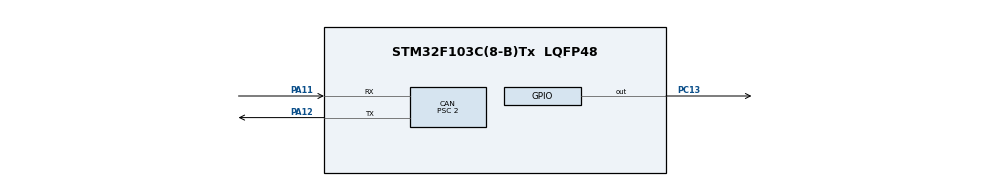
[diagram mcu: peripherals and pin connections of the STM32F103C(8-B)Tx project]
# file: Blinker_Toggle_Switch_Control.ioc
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CAN.BS1=CAN_BS1_13TQ
CAN.BS2=CAN_BS2_2TQ
CAN.CalculateBaudRate=250000
CAN.CalculateTimeBit=4000
CAN.CalculateTimeQuantum=250.0
CAN.Prescaler=2
Mcu.Family=STM32F1
Mcu.Name=STM32F103C(8-B)Tx
Mcu.Package=LQFP48
NVIC.PriorityGroup=NVIC_PRIORITYGROUP_4
NVIC.TIM1_UP_IRQn=true\:15\:0\:false\:false\:true\:false\:true\:true
NVIC.TimeBase=TIM1_UP_IRQn
NVIC.TimeBaseIP=TIM1
PA11.Mode=CAN_Activate
PA11.Signal=CAN_RX
PA12.Mode=CAN_Activate
PA12.Signal=CAN_TX
PA13.Mode=Serial_Wire
PA13.Signal=SYS_JTMS-SWDIO
PA14.Mode=Serial_Wire
PA14.Signal=SYS_JTCK-SWCLK
PC13-TAMPER-RTC.Signal=GPIO_Output
ProjectManager.HeapSize=0x200
ProjectManager.StackSize=0x400
ProjectManager.TargetToolchain=CMake
RCC.APB1Freq_Value=8000000
RCC.APB2Freq_Value=8000000
VP_SYS_VS_tim1.Mode=TIM1
board=custom

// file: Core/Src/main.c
/* USER CODE BEGIN Header */
/**
  ******************************************************************************
  * @file           : main.c
  * @brief          : Main program body
  ******************************************************************************
  * @attention
  *
  * Copyright (c) 2025 STMicroelectronics.
  * All rights reserved.
  *
  * This software is licensed under terms that can be found in the LICENSE file
  * in the root directory of this software component.
  * If no LICENSE file comes with this software, it is provided AS-IS.
  *
  ******************************************************************************
  */
/* USER CODE END Header */
#include "main.h"

/* USER CODE BEGIN PD */

//#define TOGGLE_INTERVAL_MS 500
#define POLLING_INTERVAL_MS 5 // Poll every 5ms to allow debouncing

/* USER CODE END PD */

CAN_HandleTypeDef hcan;

/* USER CODE BEGIN PV */

uint8_t blinker_state = HBLINKER_enuBlinker_OFF;
uint32_t last_toggle_time = 0;
uint8_t led_state = 0;
uint32_t last_poll_time = 0;

static TaskHandle_t Main_xBlinkerSwitchCANTaskHandle = NULL;

/* USER CODE END PV */

void SystemClock_Config(void);
static void MX_GPIO_Init(void);
static void MX_CAN_Init(void);
/* USER CODE BEGIN PFP */

void Main_vBlinkerSwitchCANTask(void *Copy_pvParams);

void CAN_Tx(HBLINKER_enuBlinkerState_t Copy_pvU8SwitchState);

/* USER CODE END PFP */

int main(void)
{

  /* USER CODE BEGIN 1 */

  BaseType_t Loc_xTaskStatus = pdFAIL;

  /* USER CODE END 1 */

  /* MCU Configuration--------------------------------------------------------*/

  /* Reset of all peripherals, Initializes the Flash interface and the Systick. */
  HAL_Init();

  /* Configure the system clock */
  SystemClock_Config();

  /* Initialize all configured peripherals */
  MX_GPIO_Init();
  MX_CAN_Init();
  /* USER CODE BEGIN 2 */

  HBLINKER_vInit(); // Initialize the blinker driver (configures PA1, PA2)
  //HAL_GPIO_WritePin(GPIOC, GPIO_PIN_13, GPIO_PIN_SET); // LED off (active low)

  Loc_xTaskStatus = xTaskCreate(&Main_vBlinkerSwitchCANTask, "BlinkerSwitchCANTask", 200UL, NULL, 0UL, &Main_xBlinkerSwitchCANTaskHandle);
  configASSERT(Loc_xTaskStatus == pdPASS);

  // CAN go to normal mode
  CAN_FilterTypeDef sFilterConfig;

  sFilterConfig.FilterBank = 0;
  sFilterConfig.FilterMode = CAN_FILTERMODE_IDMASK;
  sFilterConfig.FilterScale = CAN_FILTERSCALE_32BIT;
  sFilterConfig.FilterIdHigh = 0x0000;
  sFilterConfig.FilterIdLow = 0x0000;
  sFilterConfig.FilterMaskIdHigh = 0x0000;
  sFilterConfig.FilterMaskIdLow = 0x0000;
  sFilterConfig.FilterFIFOAssignment = CAN_FILTER_FIFO0;
  sFilterConfig.FilterActivation = ENABLE;
  sFilterConfig.SlaveStartFilterBank = 14;

  HAL_CAN_ConfigFilter(&hcan, &sFilterConfig);

  HAL_CAN_Start(&hcan);

  vTaskStartScheduler();

  /* USER CODE END 2 */

  /* Infinite loop */
  while (1)
  {

  }
}

void SystemClock_Config(void)
{
  RCC_OscInitTypeDef RCC_OscInitStruct = {0};
  RCC_ClkInitTypeDef RCC_ClkInitStruct = {0};

  /** Initializes the RCC Oscillators according to the specified parameters
  * in the RCC_OscInitTypeDef structure.
  */
  RCC_OscInitStruct.OscillatorType = RCC_OSCILLATORTYPE_HSI;
  RCC_OscInitStruct.HSIState = RCC_HSI_ON;
  RCC_OscInitStruct.HSICalibrationValue = RCC_HSICALIBRATION_DEFAULT;
  RCC_OscInitStruct.PLL.PLLState = RCC_PLL_NONE;
  if (HAL_RCC_OscConfig(&RCC_OscInitStruct) != HAL_OK)
  {
    Error_Handler();
  }

  /** Initializes the CPU, AHB and APB buses clocks
  */
  RCC_ClkInitStruct.ClockType = RCC_CLOCKTYPE_HCLK|RCC_CLOCKTYPE_SYSCLK
                              |RCC_CLOCKTYPE_PCLK1|RCC_CLOCKTYPE_PCLK2;
  RCC_ClkInitStruct.SYSCLKSource = RCC_SYSCLKSOURCE_HSI;
  RCC_ClkInitStruct.AHBCLKDivider = RCC_SYSCLK_DIV1;
  RCC_ClkInitStruct.APB1CLKDivider = RCC_HCLK_DIV1;
  RCC_ClkInitStruct.APB2CLKDivider = RCC_HCLK_DIV1;

  if (HAL_RCC_ClockConfig(&RCC_ClkInitStruct, FLASH_LATENCY_0) != HAL_OK)
  {
    Error_Handler();
  }
}

static void MX_CAN_Init(void)
{

  hcan.Instance = CAN1;
  hcan.Init.Prescaler = 2;
  hcan.Init.Mode = CAN_MODE_NORMAL;
  hcan.Init.SyncJumpWidth = CAN_SJW_1TQ;
  hcan.Init.TimeSeg1 = CAN_BS1_13TQ;
  hcan.Init.TimeSeg2 = CAN_BS2_2TQ;
  hcan.Init.TimeTriggeredMode = DISABLE;
  hcan.Init.AutoBusOff = DISABLE;
  hcan.Init.AutoWakeUp = DISABLE;
  hcan.Init.AutoRetransmission = DISABLE;
  hcan.Init.ReceiveFifoLocked = DISABLE;
  hcan.Init.TransmitFifoPriority = DISABLE;
  if (HAL_CAN_Init(&hcan) != HAL_OK)
  {
    Error_Handler();
  }

}

static void MX_GPIO_Init(void)
{
  //GPIO_InitTypeDef GPIO_InitStruct = {0};

  /* GPIO Ports Clock Enable */

  //__HAL_RCC_GPIOC_CLK_ENABLE();

  __HAL_RCC_GPIOA_CLK_ENABLE();

  /*Configure GPIO pin Output Level */

  //HAL_GPIO_WritePin(GPIOC, GPIO_PIN_13, GPIO_PIN_RESET);

  /*Configure GPIO pin : PC13 */

  /*GPIO_InitStruct.Pin = GPIO_PIN_13;
  GPIO_InitStruct.Mode = GPIO_MODE_OUTPUT_PP;
  GPIO_InitStruct.Pull = GPIO_NOPULL;
  GPIO_InitStruct.Speed = GPIO_SPEED_FREQ_LOW;
  HAL_GPIO_Init(GPIOC, &GPIO_InitStruct);*/

}

/* USER CODE BEGIN 4 */

void Main_vBlinkerSwitchCANTask(void *Copy_pvParams){

  TickType_t Loc_xLastWakeTime;
  const TickType_t Loc_xPeriodicity = pdMS_TO_TICKS(50);

  Loc_xLastWakeTime = xTaskGetTickCount();

  for ( ; ; )
  {
    uint32_t current_time = HAL_GetTick();
    if (current_time - last_poll_time >= POLLING_INTERVAL_MS)
    {
        if (HBLINKER_enuGetBLINKERState(HBLINKER_BLINKER_TOGGLE, &blinker_state) == HBLINKER_enuError_OK)
        {
            if (blinker_state == HBLINKER_enuBlinker_RIGHT) // RIGHT
            {
                CAN_Tx(HBLINKER_enuBlinker_RIGHT);

                /*if (current_time - last_toggle_time >= TOGGLE_INTERVAL_MS)
                {
                    led_state = !led_state;
                    HAL_GPIO_WritePin(GPIOC, GPIO_PIN_13, led_state ? GPIO_PIN_RESET : GPIO_PIN_SET);
                    last_toggle_time = current_time;
                }*/
            }
            else if (blinker_state == HBLINKER_enuBlinker_LEFT) // LEFT
            {
                CAN_Tx(HBLINKER_enuBlinker_LEFT);

                //HAL_GPIO_WritePin(GPIOC, GPIO_PIN_13, GPIO_PIN_RESET); // LED on (active low)

            }
            else // OFF
            {
                CAN_Tx(HBLINKER_enuBlinker_OFF);

                //HAL_GPIO_WritePin(GPIOC, GPIO_PIN_13, GPIO_PIN_SET); // LED off (active low)

            }
        }
        last_poll_time = current_time;
    }

    vTaskDelayUntil(&Loc_xLastWakeTime, Loc_xPeriodicity);

  }
}

void CAN_Tx(HBLINKER_enuBlinkerState_t Copy_pvU8SwitchState){
  CAN_TxHeaderTypeDef TxHeader;
  uint8_t TxData = Copy_pvU8SwitchState;
  uint32_t TxMailbox;

  TxHeader.StdId = 0x00;
  TxHeader.IDE = CAN_ID_STD;
  TxHeader.RTR = CAN_RTR_DATA;
  TxHeader.DLC = 1;

  while(HAL_CAN_GetTxMailboxesFreeLevel(&hcan) == 0); // Wait for a free mailbox

  if(HAL_CAN_AddTxMessage(&hcan,&TxHeader,&TxData,&TxMailbox) != HAL_OK){
    Error_Handler();
  }
}

/* USER CODE END 4 */

void HAL_TIM_PeriodElapsedCallback(TIM_HandleTypeDef *htim)
{
  if (htim->Instance == TIM1)
  {
    HAL_IncTick();
  }
}

void Error_Handler(void)
{
  __disable_irq();
  while (1)
  {
  }
}
